# SAM9X60 device description
Architecture: ARM926EJS; Family: SAM9; Series: SAM9X
Registers are 32-bit, read-write, no defined reset value unless marked. A register's access mark holds for its fields unless they carry their own. Offsets are from the block's base; [hi:lo] are bit positions; {n}, {i} and the like mark numbered series; 'fields as' and 'values as' point back to an identical list.

## PMC — Power Management Controller
Instances: PMC 0xFFFFFC00
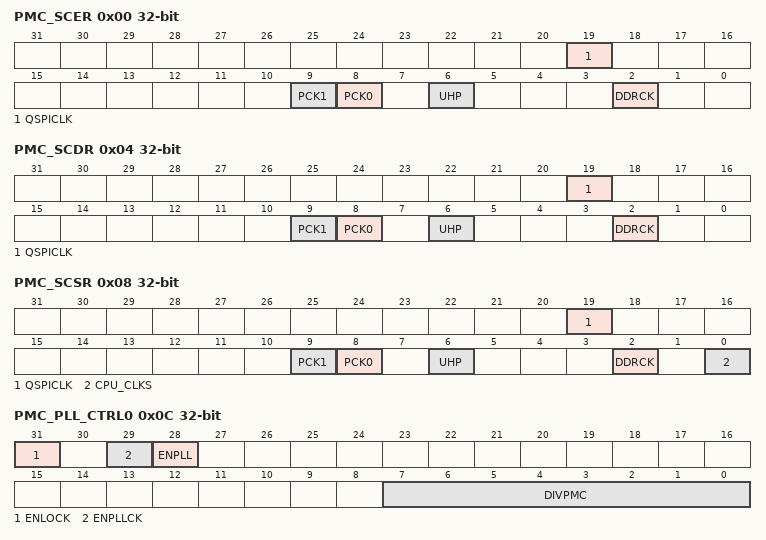
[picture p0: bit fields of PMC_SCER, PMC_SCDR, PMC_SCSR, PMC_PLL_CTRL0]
0x00 PMC_SCER wo — System Clock Enable Register
  [19] QSPICLK — QSPI 2x Clock Enable
  [9] PCK1 — Programmable Clock 1 Output Enable
  [8] PCK0 — Programmable Clock 0 Output Enable
  [6] UHP — USB Host OHCI Clocks Enable
  [2] DDRCK — MPDDRC Clock Enable
0x04 PMC_SCDR wo — System Clock Disable Register
  [19] QSPICLK — QSPI 2x Clock Disable
  [9] PCK1 — Programmable Clock 1 Output Disable
  [8] PCK0 — Programmable Clock 0 Output Disable
  [6] UHP — USB Host OHCI Clocks Disable
  [2] DDRCK — MPDDRC Clock Disable
0x08 PMC_SCSR ro — System Clock Status Register
  [19] QSPICLK — QSPI 2x Clock Status
  [9] PCK1 — Programmable Clock 1 Output Status
  [8] PCK0 — Programmable Clock 0 Output Status
  [6] UHP — USB Host OHCI Clocks Status
  [2] DDRCK — MPDDRC Clock Status
  [0] CPU_CLKS — CPU_CLK Status
0x0C PMC_PLL_CTRL0 — PLL Control Register 0
  [31] ENLOCK — Enable PLL Lock
  [29] ENPLLCK — Enable PLL Clock for PMC
  [28] ENPLL — Enable PLL
  [7:0] DIVPMC — Divider for PMC
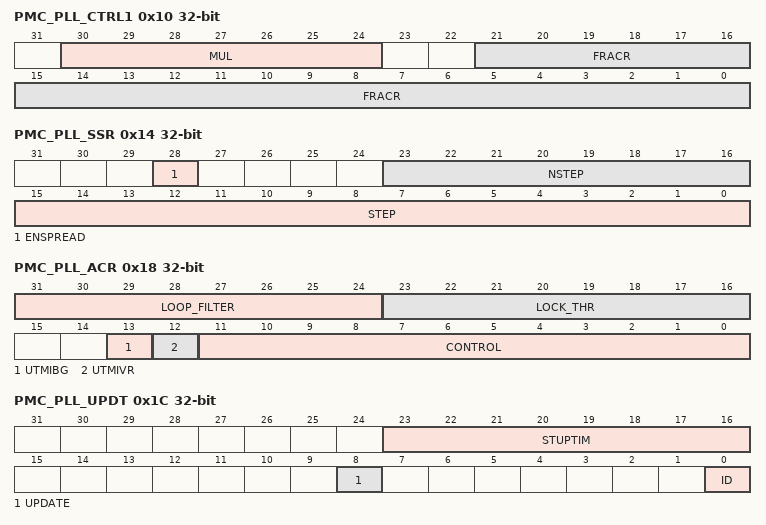
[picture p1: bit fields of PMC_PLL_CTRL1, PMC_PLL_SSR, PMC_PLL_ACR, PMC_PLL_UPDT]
0x10 PMC_PLL_CTRL1 — PLL Control Register 1
  [30:24] MUL — Multiplier Factor Value
  [21:0] FRACR — Fractional Loop Divider Setting
0x14 PMC_PLL_SSR — PLL Spread Spectrum Register
  [28] ENSPREAD — Spread Spectrum Enable
  [23:16] NSTEP — Spread Spectrum Number of Step
  [15:0] STEP — Spread Spectrum Step Size
0x18 PMC_PLL_ACR — PLL Analog Control Register
  [31:24] LOOP_FILTER — LOOP Filter Selection
  [23:16] LOCK_THR — PLL Lock Threshold Value Selection
  [13] UTMIBG — UPLL Bandgap Control
  [12] UTMIVR — UPLL Voltage Regulator Control
  [11:0] CONTROL — PLL CONTROL Value Selection
0x1C PMC_PLL_UPDT — PLL Update Register
  [23:16] STUPTIM — Startup Time
  [8] UPDATE — PLL Setting Update (write-only)
  [0] ID — PLL ID
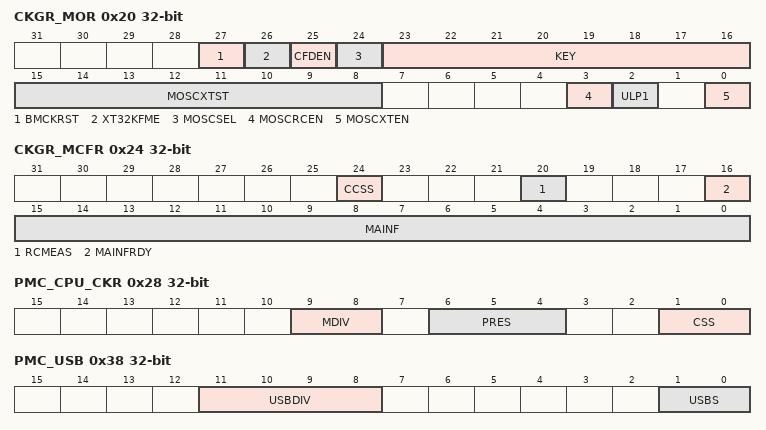
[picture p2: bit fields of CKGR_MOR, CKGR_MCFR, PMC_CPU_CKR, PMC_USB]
0x20 CKGR_MOR — Main Oscillator Register
  [27] BMCKRST — Bad MCK Clock Reset Enable
  [26] XT32KFME — 32.768 kHz Crystal Oscillator Frequency Monitoring Enable
  [25] CFDEN — Clock Failure Detector Enable
  [24] MOSCSEL — Main Clock Oscillator Selection
    0=RC (The Main RC oscillator is selected.); 1=XT (The Main crystal oscillator is selected.)
  [23:16] KEY — Write Access Password
    55=PASSWD (Writing any other value in this field aborts the write operation.Always reads as 0.)
  [15:8] MOSCXTST — Main Crystal Oscillator Startup Time
  [3] MOSCRCEN — Main RC Oscillator Enable
  [2] ULP1 — ULP Mode 1 Command (write-only)
  [0] MOSCXTEN — Main Crystal Oscillator Enable
0x24 CKGR_MCFR — Main Clock Frequency Register
  [24] CCSS — Counter Clock Source Selection
  [20] RCMEAS — RC Oscillator Frequency Measure (write-only)
  [16] MAINFRDY — Main Clock Frequency Measure Ready
  [15:0] MAINF — Main Clock Frequency
0x28 PMC_CPU_CKR — CPU Clock Register
  [9:8] MDIV — MCK Division
    0=EQ_PCK (MCK is FCLK divided by 1. MCK_2X is FCLK divided by 1.); 1=PCK_DIV2 (MCK is FCLK divided by 2. MCK_2X is FCLK divided by 1.); 2=PCK_DIV4 (MCK is FCLK divided by 4. MCK_2X is FCLK divided by 2.); 3=PCK_DIV3 (MCK is FCLK divided by 3. MCK_2X is FCLK divided by 1.5.)
  [6:4] PRES — Processor Clock Prescaler
    0=CLK_1 (Selected clock); 1=CLK_2 (Selected clock divided by 2); 2=CLK_4 (Selected clock divided by 4); 3=CLK_8 (Selected clock divided by 8); 4=CLK_16 (Selected clock divided by 16); 5=CLK_32 (Selected clock divided by 32); 6=CLK_64 (Selected clock divided by 64); 7=CLK_3 (Selected clock divided by 3)
  [1:0] CSS — MCK Source Selection
    0=SLOW_CLK (MD_SLCK is selected); 1=MAIN_CLK (MAINCK is selected); 2=PLLACK (PLLACK is selected); 3=UPLLCK (UPLL is selected)
0x38 PMC_USB — USB Clock Register
  [11:8] USBDIV — Divider for USB OHCI Clock
  [1:0] USBS — USB OHCI/EHCI Input Clock Selection
    0=PLLA (USB Clock Input is PLLACK.); 1=UPLL (USB Clock Input is UPLLCK.); 2=MAINXTAL (USB Clock Input is MAINXTALCK.)
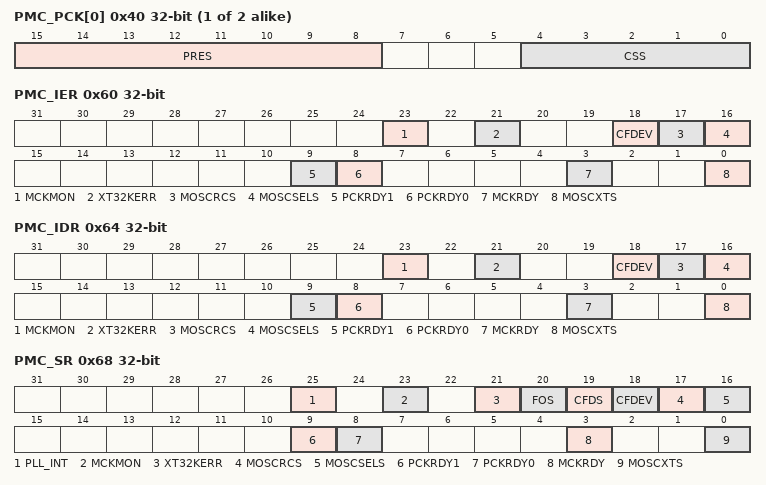
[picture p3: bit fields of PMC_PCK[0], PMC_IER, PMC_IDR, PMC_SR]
{0x40+4i} PMC_PCK[{i}] (i=0..1) — Programmable Clock Register
  [15:8] PRES — Programmable Clock Prescaler
  [4:0] CSS — Programmable Clock Source Selection
    0=MD_SLOW_CLK (MD_SLCK is selected); 1=TD_SLOW_CLOCK (TD_SLCK is selected); 2=MAINCK (MAINCK is selected); 3=MCK (MCK is selected); 4=PLLA (PLLA is selected.); 5=UPLL (UPLL is selected.)
0x60 PMC_IER wo — Interrupt Enable Register
  [23] MCKMON — Master Clock Clock Monitor Interrupt Enable
  [21] XT32KERR — 32.768 kHz Crystal Oscillator Error Interrupt Enable
  [18] CFDEV — Clock Failure Detector Event Interrupt Enable
  [17] MOSCRCS — Main RC Oscillator Status Interrupt Enable
  [16] MOSCSELS — Main Clock Source Oscillator Selection Status Interrupt Enable
  [9] PCKRDY1 — Programmable Clock Ready 1 Interrupt Enable
  [8] PCKRDY0 — Programmable Clock Ready 0 Interrupt Enable
  [3] MCKRDY — Master Clock Ready Interrupt Enable
  [0] MOSCXTS — Main Crystal Oscillator Status Interrupt Enable
0x64 PMC_IDR wo — Interrupt Disable Register
  [23] MCKMON — Master Clock Clock Monitor Interrupt Disable
  [21] XT32KERR — 32.768 kHz Crystal Oscillator Error Interrupt Disable
  [18] CFDEV — Clock Failure Detector Event Interrupt Disable
  [17] MOSCRCS — Main RC Status Interrupt Disable
  [16] MOSCSELS — Main Clock Source Oscillator Selection Status Interrupt Disable
  [9] PCKRDY1 — Programmable Clock Ready 1 Interrupt Disable
  [8] PCKRDY0 — Programmable Clock Ready 0 Interrupt Disable
  [3] MCKRDY — Master Clock Ready Interrupt Disable
  [0] MOSCXTS — Main Crystal Oscillator Status Interrupt Disable
0x68 PMC_SR ro — Status Register
  [25] PLL_INT — PLL Interrupt Status
  [23] MCKMON — Master Clock Clock Monitor Error
  [21] XT32KERR — Slow Crystal Oscillator Error
  [20] FOS — Clock Failure Detector Fault Output Status
  [19] CFDS — Clock Failure Detector Status
  [18] CFDEV — Clock Failure Detector Event
  [17] MOSCRCS — Main RC Oscillator Status
  [16] MOSCSELS — Main Clock Source Oscillator Selection Status
  [9] PCKRDY1 — Programmable Clock Ready Status
  [8] PCKRDY0 — Programmable Clock Ready Status
  [3] MCKRDY — Master Clock Status
  [0] MOSCXTS — Main Crystal Oscillator Status
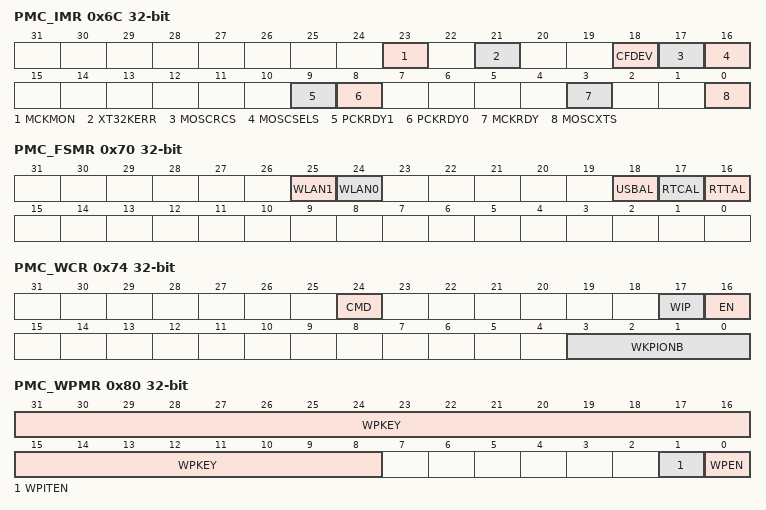
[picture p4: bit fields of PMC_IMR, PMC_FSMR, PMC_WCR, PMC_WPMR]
0x6C PMC_IMR ro — Interrupt Mask Register
  [23] MCKMON — Master Clock Monitor Error Interrupt Mask
  [21] XT32KERR — 32.768 kHz Crystal Oscillator Error Interrupt Mask
  [18] CFDEV — Clock Failure Detector Event Interrupt Mask
  [17] MOSCRCS — Main RC Status Interrupt Mask
  [16] MOSCSELS — Main Clock Source Oscillator Selection Status Interrupt Mask
  [9] PCKRDY1 — Programmable Clock Ready 1 Interrupt Mask
  [8] PCKRDY0 — Programmable Clock Ready 0 Interrupt Mask
  [3] MCKRDY — Master Clock Ready Interrupt Mask
  [0] MOSCXTS — Main Crystal Oscillator Status Interrupt Mask
0x70 PMC_FSMR — Fast Startup Mode Register
  [25] WLAN1 — Wakeup on LAN[x]
  [24] WLAN0 — Wakeup on LAN[x]
  [18] USBAL — USB Alarm Enable
  [17] RTCAL — RTC Alarm Enable
  [16] RTTAL — RTT Alarm Enable
0x74 PMC_WCR — Wakeup Control Register
  [24] CMD — Command
  [17] WIP — Wakeup Input Polarity
  [16] EN — Wakeup Input Enable
  [3:0] WKPIONB — Wakeup Input Number
0x78 PMC_FOCR wo — Fault Output Clear Register
  [0] FOCLR — Fault Output Clear
0x80 PMC_WPMR — Write Protection Mode Register
  [31:8] WPKEY — Write Protection Key
    0x504D43=PASSWD (Writing any other value in this field aborts the write operation of the WPEN bit. Always reads as 0.)
  [1] WPITEN — Write Protection Interrupt Enable
  [0] WPEN — Write Protection Enable
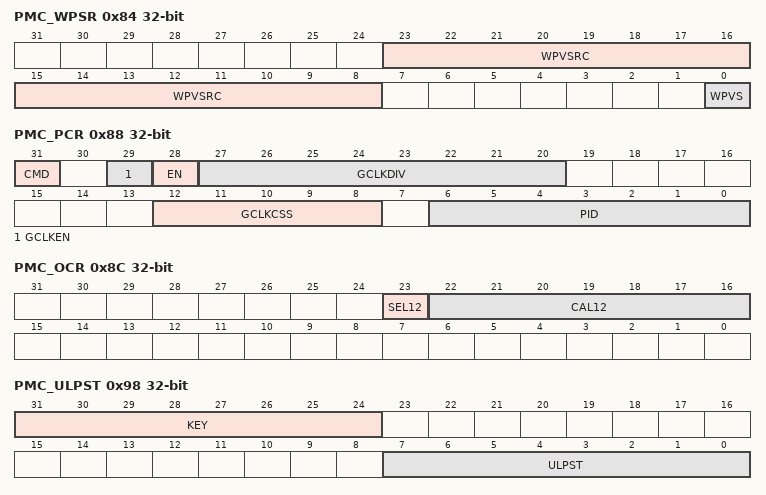
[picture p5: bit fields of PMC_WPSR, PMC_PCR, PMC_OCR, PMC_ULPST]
0x84 PMC_WPSR ro — Write Protection Status Register
  [23:8] WPVSRC — Write Protection Violation Source
  [0] WPVS — Write Protection Violation Status
0x88 PMC_PCR — Peripheral Control Register
  [31] CMD — Command
  [29] GCLKEN — Generic Clock Enable
  [28] EN — Enable
  [27:20] GCLKDIV — Generic Clock Division Ratio
  [12:8] GCLKCSS — Generic Clock Source Selection
    values as PMC_PCK[0].CSS
  [6:0] PID — Peripheral ID
0x8C PMC_OCR — Oscillator Calibration Register
  [23] SEL12 — Selection of Main RC Oscillator Calibration Bits
  [22:16] CAL12 — Main RC Oscillator Calibration Bits
0x98 PMC_ULPST — ULP Startup Time Register
  [31:24] KEY — Write Access Password
    90=PASSWD (Writing any other value in this field aborts the write operation.Always reads as 0.)
  [7:0] ULPST — Ultra Low Power Mode Startup Time
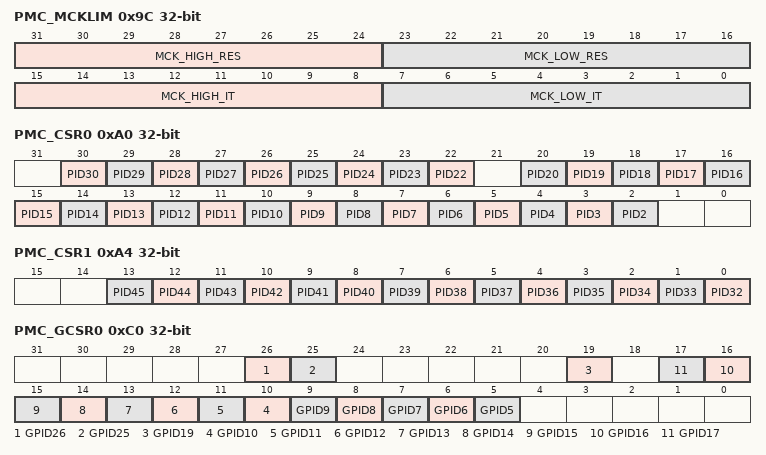
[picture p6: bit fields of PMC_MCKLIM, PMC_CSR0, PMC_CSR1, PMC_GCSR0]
0x9C PMC_MCKLIM — MCK Monitor Limits Register
  [31:24] MCK_HIGH_RES — MCK Monitoring High Reset Limit
  [23:16] MCK_LOW_RES — MCK Monitoring Low RESET Limit
  [15:8] MCK_HIGH_IT — MCK Monitoring High IT Limit
  [7:0] MCK_LOW_IT — MCK Monitoring Low IT Limit
0xA0 PMC_CSR0 ro — Peripheral Clock Status Register 0
  [n] PID{n} (n=22..30) — Peripheral Clock {n} Status
  [n] PID{n} (n=2..20) — Peripheral Clock {n} Status
0xA4 PMC_CSR1 ro — Peripheral Clock Status Register 1
  [n-32] PID{n} (n=32..45) — Peripheral Clock {n} Status
0xA8 PMC_CSR2 ro — Peripheral Clock Status Register 2
0xAC PMC_CSR3 ro — Peripheral Clock Status Register 3
0xC0 PMC_GCSR0 ro — Generic Clock Status Register 0
  [26] GPID26 — Generic Clock 26 Status
  [25] GPID25 — Generic Clock 25 Status
  [19] GPID19 — Generic Clock 19 Status
  [n] GPID{n} (n=5..17) — Generic Clock {n} Status
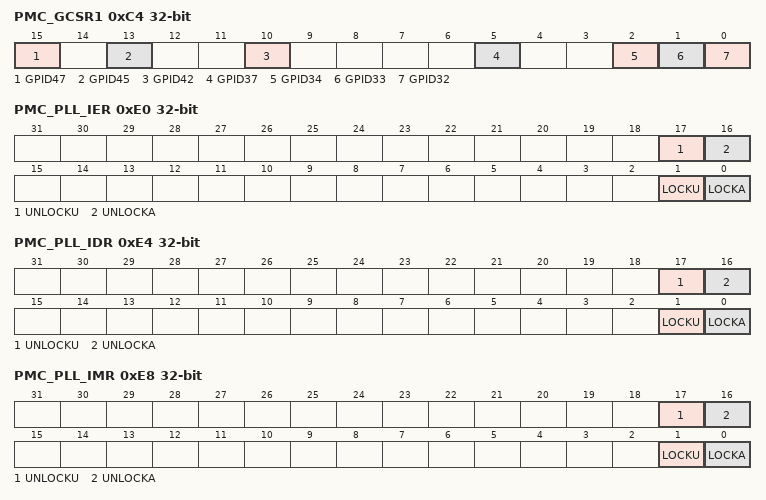
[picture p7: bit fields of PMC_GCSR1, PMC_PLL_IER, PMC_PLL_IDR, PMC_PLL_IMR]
0xC4 PMC_GCSR1 ro — Generic Clock Status Register 1
  [15] GPID47 — Generic Clock 47 Status
  [13] GPID45 — Generic Clock 45 Status
  [10] GPID42 — Generic Clock 42 Status
  [5] GPID37 — Generic Clock 37 Status
  [2] GPID34 — Generic Clock 34 Status
  [1] GPID33 — Generic Clock 33 Status
  [0] GPID32 — Generic Clock 32 Status
0xC8 PMC_GCSR2 ro — Generic Clock Status Register 2
0xCC PMC_GCSR3 ro — Generic Clock Status Register 3
0xE0 PMC_PLL_IER wo — PLL Interrupt Enable Register
  [17] UNLOCKU — UPLL Unlock Interrupt Enable
  [16] UNLOCKA — PLLA Unlock Interrupt Enable
  [1] LOCKU — UPLL Lock Interrupt Enable
  [0] LOCKA — PLLA Lock Interrupt Enable
0xE4 PMC_PLL_IDR wo — PLL Interrupt Disable Register
  [17] UNLOCKU — UPLL Unlock Interrupt Disable
  [16] UNLOCKA — PLLA Unlock Interrupt Disable
  [1] LOCKU — UPLL Lock Interrupt Disable
  [0] LOCKA — PLLA Lock Interrupt Disable
0xE8 PMC_PLL_IMR ro — PLL Interrupt Mask Register
  [17] UNLOCKU — UPLL Unlock Interrupt Mask
  [16] UNLOCKA — PLLA Unlock Interrupt Mask
  [1] LOCKU — UPLL Lock Interrupt Mask
  [0] LOCKA — PLLA Lock Interrupt Mask
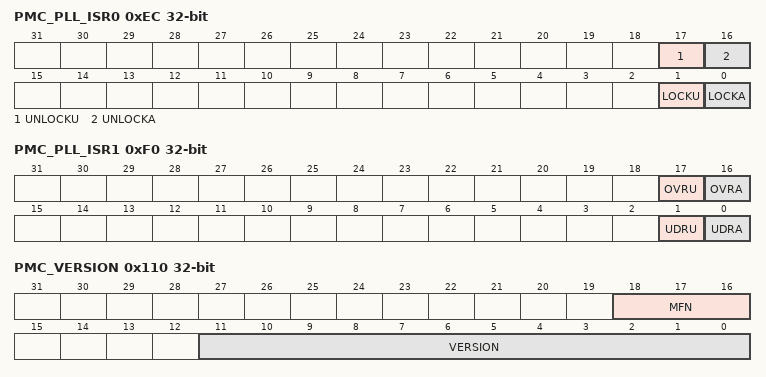
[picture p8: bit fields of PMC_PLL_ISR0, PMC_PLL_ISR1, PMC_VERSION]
0xEC PMC_PLL_ISR0 ro — PLL Interrupt Status Register 0
  [17] UNLOCKU — UPLL Unlock Interrupt Status
  [16] UNLOCKA — PLLA Unlock Interrupt Status
  [1] LOCKU — UPLL Lock Interrupt Status
  [0] LOCKA — PLLA Lock Interrupt Status
0xF0 PMC_PLL_ISR1 ro — PLL Interrupt Status Register 1
  [17] OVRU — UPLL Overflow
  [16] OVRA — PLLA Overflow
  [1] UDRU — UPLL Underflow
  [0] UDRA — PLLA Underflow
0x110 PMC_VERSION ro — Version Register
  [18:16] MFN — Metal Fix Number
  [11:0] VERSION — Version of the Hardware Module
